VERSION ""

NS_ :

BS_:

BU_: XXX

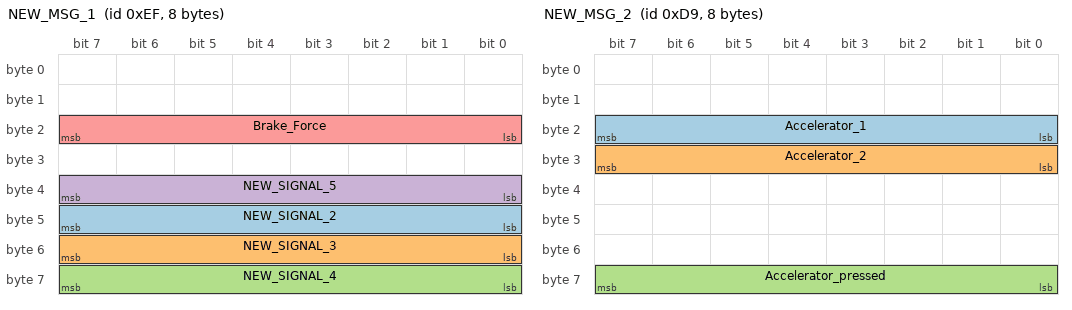
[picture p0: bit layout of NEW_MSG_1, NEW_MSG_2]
BO_ 239 NEW_MSG_1: 8 XXX
 SG_ NEW_SIGNAL_2 : 47|8@0+ (1,0) [0|255] "" XXX
 SG_ NEW_SIGNAL_3 : 55|8@0+ (1,0) [0|255] "" XXX
 SG_ NEW_SIGNAL_4 : 63|8@0+ (1,0) [0|255] "" XXX
 SG_ NEW_SIGNAL_5 : 39|8@0+ (1,0) [0|255] "" XXX
 SG_ Brake_Force : 16|8@1+ (1,0) [0|255] "" XXX

BO_ 217 NEW_MSG_2: 8 XXX
 SG_ Accelerator_1 : 23|8@0+ (1,0) [0|255] "" XXX
 SG_ Accelerator_2 : 31|8@0+ (1,0) [0|255] "" XXX
 SG_ Accelerator_pressed : 63|8@0+ (1,0) [0|255] "" XXX

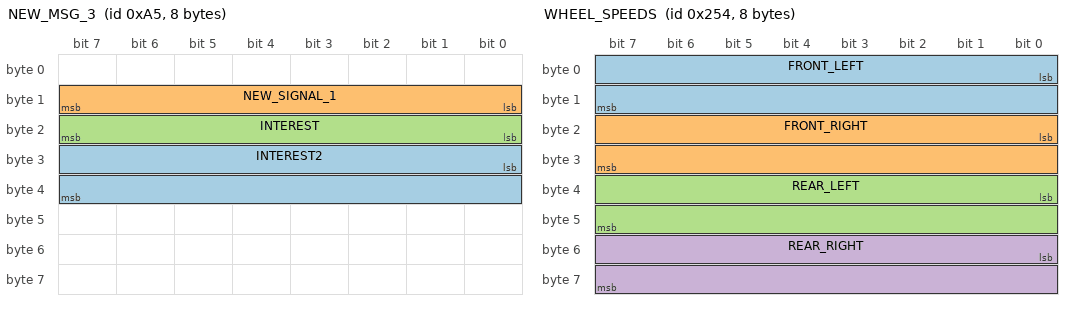
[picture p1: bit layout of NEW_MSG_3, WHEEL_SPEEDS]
BO_ 165 NEW_MSG_3: 8 XXX
 SG_ INTEREST2 : 24|16@1+ (1,0) [0|65535] "" XXX
 SG_ NEW_SIGNAL_1 : 15|8@0+ (1,0) [0|255] "" XXX
 SG_ INTEREST : 16|8@1+ (1,0) [0|255] "" XXX

BO_ 596 WHEEL_SPEEDS: 8 XXX
 SG_ FRONT_LEFT : 0|16@1+ (1,0) [0|65535] "" XXX
 SG_ FRONT_RIGHT : 16|16@1+ (1,0) [0|255] "" XXX
 SG_ REAR_LEFT : 32|16@1+ (1,0) [0|65535] "" XXX
 SG_ REAR_RIGHT : 48|16@1+ (1,0) [0|65535] "" XXX

BO_ 407 NEW_MSG_5: 8 XXX
 SG_ NEW_SIGNAL_1 : 0|16@1+ (1,0) [0|65535] "" XXX

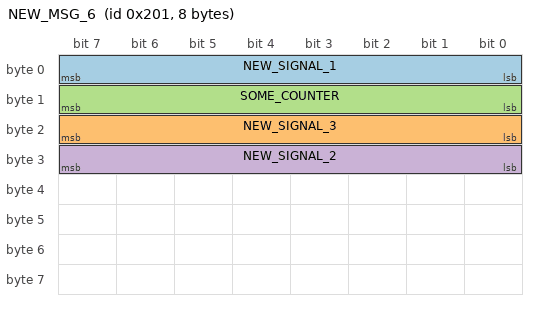
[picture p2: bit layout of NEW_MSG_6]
BO_ 513 NEW_MSG_6: 8 XXX
 SG_ NEW_SIGNAL_1 : 7|8@0+ (1,0) [0|255] "" XXX
 SG_ NEW_SIGNAL_3 : 23|8@0+ (1,0) [0|255] "" XXX
 SG_ SOME_COUNTER : 15|8@0+ (1,0) [0|255] "" XXX
 SG_ NEW_SIGNAL_2 : 31|8@0+ (1,0) [0|255] "" XXX

BO_ 518 NEW_MSG_7: 8 XXX

BO_ 709 NEW_MSG_8: 8 XXX
 SG_ NEW_SIGNAL_2 : 16|16@1+ (1,0) [0|65535] "" XXX
 SG_ NEW_SIGNAL_1 : 15|8@0+ (1,0) [0|255] "" XXX

BO_ 256 NEW_MSG_9: 8 XXX
 SG_ ePower : 24|16@1+ (1,0) [0|255] "" XXX

BO_ 417 NEW_MSG_10: 8 XXX
 SG_ Speed : 16|16@1+ (0.015625,0) [0|65535] "KPH" XXX

BO_ 770 NEW_MSG_11: 8 XXX
 SG_ STEERING_ANGLE : 16|16@1+ (0.002747,-90) [0|65535] "DEG" XXX

BO_ 817 NEW_MSG_4: 8 XXX

BO_ 464 NEW_MSG_12: 8 XXX
 SG_ SOME_COUNTER : 0|16@1+ (1,0) [0|65535] "" XXX

BO_ 772 NEW_MSG_13: 8 XXX
 SG_ INTERESTING : 16|16@1+ (1,0) [0|65535] "" XXX

BO_ 883 NEW_MSG_14: 8 XXX
 SG_ NEW_SIGNAL_1 : 0|16@1+ (1,0) [0|255] "" XXX

BO_ 274 NEW_MSG_15: 8 XXX
 SG_ MAYBE_STR : 0|16@1+ (1,0) [0|65535] "" XXX

BO_ 769 NEW_MSG_16: 8 XXX
 SG_ STEER_ANGLE : 16|16@1+ (1,0) [0|65535] "" XXX

BO_ 779 NEW_MSG_17: 8 XXX
 SG_ COUNTER : 0|16@1+ (1,0) [0|65535] "" XXX

BO_ 415 NEW_MSG_18: 8 XXX
 SG_ STEER_ANGL : 16|16@1+ (1,0) [0|65535] "" XXX

BO_ 410 STEER_RATE: 8 XXX
 SG_ STEER_RATE : 16|16@1+ (0.1,-3260) [0|65535] "DEG/S" XXX

BO_ 195 NEW_MSG_19: 8 XXX
 SG_ NEW_SIGNAL_1 : 0|8@1+ (1,0) [0|65535] "" XXX

BO_ 314 NEW_MSG_20: 8 XXX
